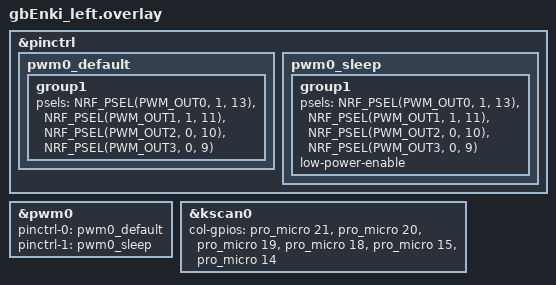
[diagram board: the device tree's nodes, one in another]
/*
 * Copyright (c) 2020 Pete Johanson
 *
 * SPDX-License-Identifier: MIT
 */

&pinctrl {
    // Other Pinctrl definitions go here
    pwm0_default: pwm0_default {
        group1 {
            psels = <NRF_PSEL(PWM_OUT0, 0, 10)>,  // LED 0 на пине P0.10 (pin 16)
                    <NRF_PSEL(PWM_OUT1, 0, 9)>,   // LED 1 на пине P0.09 (pin 10)
                    <NRF_PSEL(PWM_OUT2, 1, 4)>;   // LED 2 на пине P1.04 (pin 8)
        };
    };
    pwm0_sleep: pwm0_sleep {
        group1 {
            psels = <NRF_PSEL(PWM_OUT0, 0, 10)>,  // LED 0 на пине P0.10 (pin 16)
                    <NRF_PSEL(PWM_OUT1, 0, 9)>,   // LED 1 на пине P0.09 (pin 10)
                    <NRF_PSEL(PWM_OUT2, 1, 4)>;   // LED 2 на пине P1.04 (pin 8)
            low-power-enable;
        };
    };
};


&pwm0 {
    status = "okay";
    pinctrl-0 = <&pwm0_default>;
    pinctrl-1 = <&pwm0_sleep>;
    pinctrl-names = "default", "sleep";
};

&pinctrl {
    // Other Pinctrl definitions go here
    pwm0_default: pwm0_default {
        group1 {
            psels = <NRF_PSEL(PWM_OUT0, 1, 13)>, // LED 0
                    <NRF_PSEL(PWM_OUT1, 1, 11)>, // LED 1
                    <NRF_PSEL(PWM_OUT2, 0, 10)>, // LED 2
                    <NRF_PSEL(PWM_OUT3, 0, 9)>;  // LED 3
        };
    };
    pwm0_sleep: pwm0_sleep {
        group1 {
            psels = <NRF_PSEL(PWM_OUT0, 1, 13)>, // LED 0
                    <NRF_PSEL(PWM_OUT1, 1, 11)>, // LED 1
                    <NRF_PSEL(PWM_OUT2, 0, 10)>, // LED 2
                    <NRF_PSEL(PWM_OUT3, 0, 9)>;  // LED 3
            low-power-enable;
        };
    };
};
&kscan0 {
    col-gpios
        = <&pro_micro 21 GPIO_ACTIVE_HIGH>
        , <&pro_micro 20 GPIO_ACTIVE_HIGH>
        , <&pro_micro 19 GPIO_ACTIVE_HIGH>
        , <&pro_micro 18 GPIO_ACTIVE_HIGH>
        , <&pro_micro 15 GPIO_ACTIVE_HIGH>
        , <&pro_micro 14 GPIO_ACTIVE_HIGH>
        ;
};
